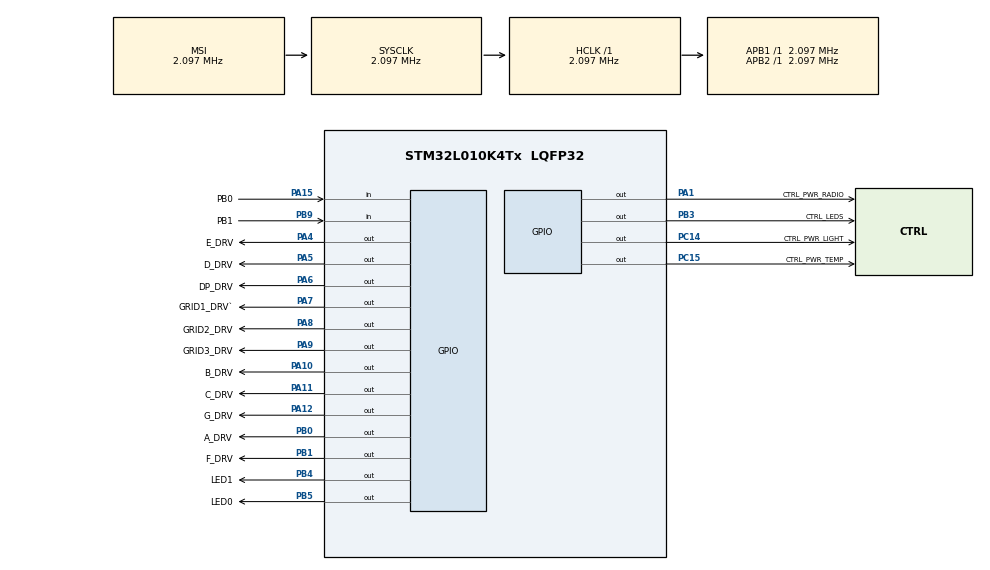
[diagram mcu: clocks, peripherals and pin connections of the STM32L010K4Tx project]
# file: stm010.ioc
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Mcu.Family=STM32L0
Mcu.Name=STM32L010K4Tx
Mcu.Package=LQFP32
PA0-CK_IN.GPIO_Label=SENSE_LIGHT
PA0-CK_IN.Signal=ADC_IN0
PA1.GPIO_Label=CTRL_PWR_RADIO
PA1.PinState=GPIO_PIN_SET
PA1.Signal=GPIO_Output
PA10.GPIO_Label=B_DRV
PA10.Signal=GPIO_Output
PA11.GPIO_Label=C_DRV
PA11.Signal=GPIO_Output
PA12.GPIO_Label=G_DRV
PA12.Signal=GPIO_Output
PA13.Mode=Serial_Wire
PA13.Signal=SYS_SWDIO
PA14.Mode=Serial_Wire
PA14.Signal=SYS_SWCLK
PA15.GPIO_Label=PB0
PA15.GPIO_PuPd=GPIO_PULLUP
PA15.Signal=GPIO_Input
PA3.GPIO_Label=SENSE_PWR
PA3.Signal=ADC_IN3
PA4.GPIO_Label=E_DRV
PA4.Signal=GPIO_Output
PA5.GPIO_Label=D_DRV
PA5.Signal=GPIO_Output
PA6.GPIO_Label=DP_DRV
PA6.Signal=GPIO_Output
PA7.GPIO_Label=GRID1_DRV`
PA7.Signal=GPIO_Output
PA8.GPIO_Label=GRID2_DRV
PA8.Signal=GPIO_Output
PA9.GPIO_Label=GRID3_DRV
PA9.Signal=GPIO_Output
PB0.GPIO_Label=A_DRV
PB0.Signal=GPIO_Output
PB1.GPIO_Label=F_DRV
PB1.Signal=GPIO_Output
PB3.GPIO_Label=CTRL_LEDS
PB3.PinState=GPIO_PIN_SET
PB3.Signal=GPIO_Output
PB4.GPIO_Label=LED1
PB4.Signal=GPIO_Output
PB5.GPIO_Label=LED0
PB5.PinState=GPIO_PIN_SET
PB5.Signal=GPIO_Output
PB9-BOOT0.GPIO_Label=PB1
PB9-BOOT0.Signal=GPIO_Input
PC14-OSC32_IN.GPIO_Label=CTRL_PWR_LIGHT
PC14-OSC32_IN.PinState=GPIO_PIN_SET
PC14-OSC32_IN.Signal=GPIO_Output
PC15-OSC32_OUT.GPIO_Label=CTRL_PWR_TEMP
PC15-OSC32_OUT.PinState=GPIO_PIN_SET
PC15-OSC32_OUT.Signal=GPIO_Output
ProjectManager.HeapSize=0x200
ProjectManager.StackSize=0x400
ProjectManager.TargetToolchain=Makefile
RCC.AHBFreq_Value=2097000
RCC.APB1Freq_Value=2097000
RCC.APB1TimFreq_Value=2097000
RCC.APB2Freq_Value=2097000
RCC.APB2TimFreq_Value=2097000
RCC.HCLKFreq_Value=2097000
RCC.HSE_VALUE=8000000
RCC.HSI16_VALUE=16000000
RCC.HSI_VALUE=16000000
RCC.LSE_VALUE=32768
RCC.MSI_VALUE=2097000
RCC.SYSCLKFreq_VALUE=2097000
RCC.VCOOutputFreq_Value=48000000
board=custom

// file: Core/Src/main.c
/* USER CODE BEGIN Header */
/**
  ******************************************************************************
  * @file           : main.c
  * @brief          : Main program body
  ******************************************************************************
  * @attention
  *
  * Copyright (c) 2024 STMicroelectronics.
  * All rights reserved.
  *
  * This software is licensed under terms that can be found in the LICENSE file
  * in the root directory of this software component.
  * If no LICENSE file comes with this software, it is provided AS-IS.
  *
  ******************************************************************************
  */
/* USER CODE END Header */
#include "main.h"
#include "gpio.h"

/* USER CODE BEGIN PV */
/*
uint16_t temp_val;
uint16_t humid_val;
uint16_t light_val;
uint16_t battery_val;
uint8_t data_buff[7];
*/
/* USER CODE END PV */

void SystemClock_Config(void);

int main(void)
{
  /* USER CODE BEGIN 1 */
  RCC->IOPENR = 0x02;
  GPIOB->MODER = 0b0000010101000000;
  GPIOB->ODR = 0x0028;
  while(1);
  /* USER CODE END 1 */

  /* MCU Configuration--------------------------------------------------------*/

  /* Reset of all peripherals, Initializes the Flash interface and the Systick. */
  HAL_Init();

  /* Configure the system clock */
  SystemClock_Config();

  /* Initialize all configured peripherals */
  MX_GPIO_Init();

  /* Infinite loop */
  /* USER CODE BEGIN WHILE */
  while (1)
  {
    /*
    temp_val++;
    humid_val++;
    light_val++;
    battery_val++;
    */
    HAL_Delay(1000);
    /* USER CODE END WHILE */

  }
}

void SystemClock_Config(void)
{
  RCC_OscInitTypeDef RCC_OscInitStruct = {0};
  RCC_ClkInitTypeDef RCC_ClkInitStruct = {0};

  /** Configure the main internal regulator output voltage
  */
  __HAL_PWR_VOLTAGESCALING_CONFIG(PWR_REGULATOR_VOLTAGE_SCALE1);

  /** Initializes the RCC Oscillators according to the specified parameters
  * in the RCC_OscInitTypeDef structure.
  */
  RCC_OscInitStruct.OscillatorType = RCC_OSCILLATORTYPE_MSI;
  RCC_OscInitStruct.MSIState = RCC_MSI_ON;
  RCC_OscInitStruct.MSICalibrationValue = 0;
  RCC_OscInitStruct.MSIClockRange = RCC_MSIRANGE_5;
  RCC_OscInitStruct.PLL.PLLState = RCC_PLL_NONE;
  if (HAL_RCC_OscConfig(&RCC_OscInitStruct) != HAL_OK)
  {
    Error_Handler();
  }

  /** Initializes the CPU, AHB and APB buses clocks
  */
  RCC_ClkInitStruct.ClockType = RCC_CLOCKTYPE_HCLK|RCC_CLOCKTYPE_SYSCLK
                              |RCC_CLOCKTYPE_PCLK1|RCC_CLOCKTYPE_PCLK2;
  RCC_ClkInitStruct.SYSCLKSource = RCC_SYSCLKSOURCE_MSI;
  RCC_ClkInitStruct.AHBCLKDivider = RCC_SYSCLK_DIV1;
  RCC_ClkInitStruct.APB1CLKDivider = RCC_HCLK_DIV1;
  RCC_ClkInitStruct.APB2CLKDivider = RCC_HCLK_DIV1;

  if (HAL_RCC_ClockConfig(&RCC_ClkInitStruct, FLASH_LATENCY_0) != HAL_OK)
  {
    Error_Handler();
  }
}

void Error_Handler(void)
{
  __disable_irq();
  while (1)
  {
  }
}
